AUTOSAR XML (schema 4-2-2)
package /STELLANTIS/EPT/ASWCs
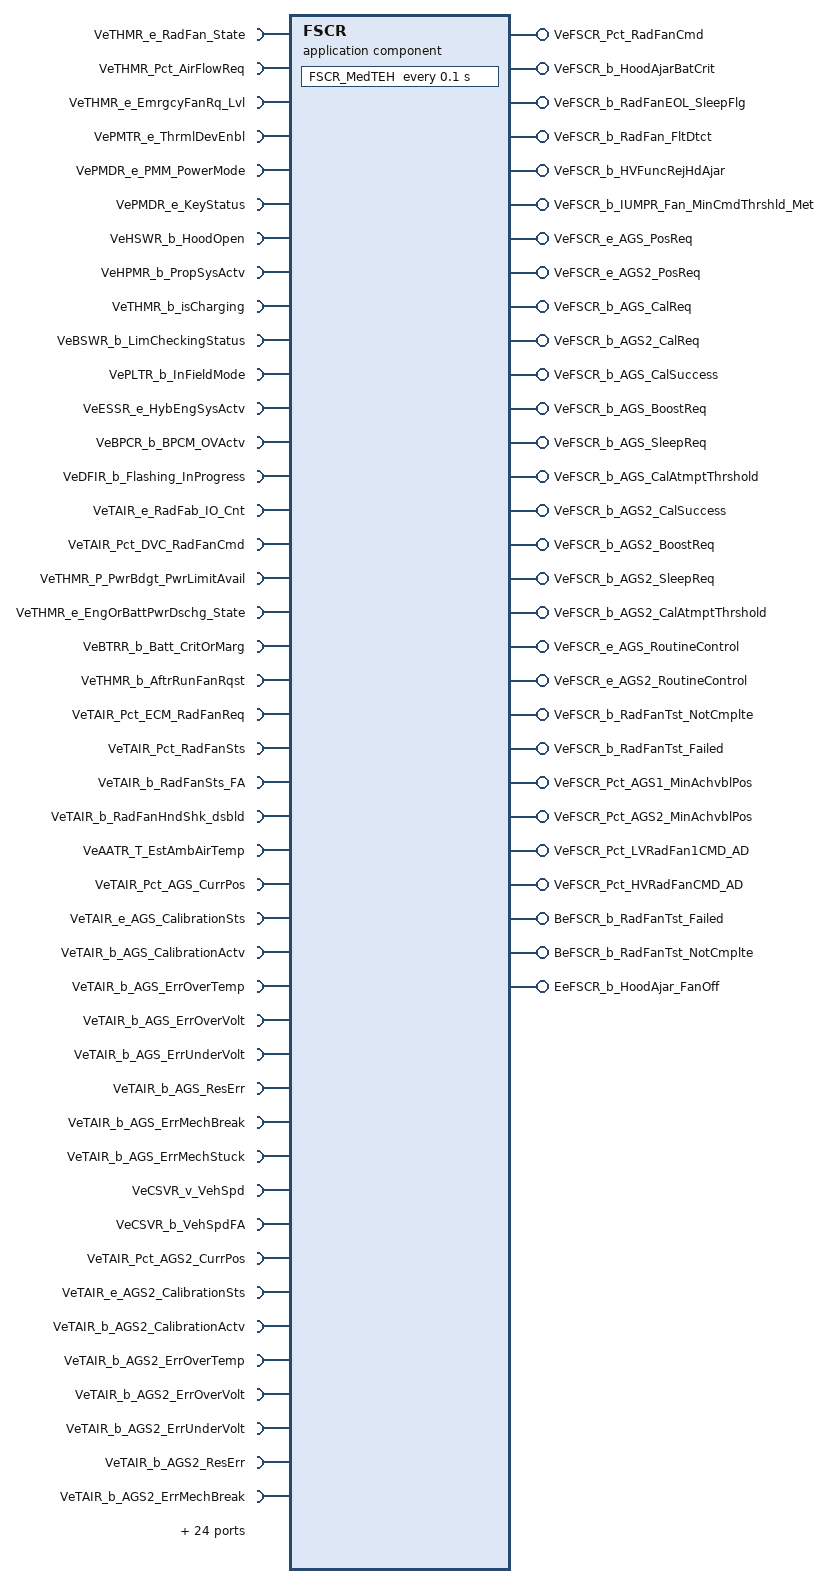
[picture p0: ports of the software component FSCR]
  application sw component type FSCR
    67 x require port:
      VeTHMR_e_RadFan_State: variation-point={short-label=vpVeTHMR_e_RadFan_State, sw-syscond=1}, nonqueued-receiver-com-spec{data-element=Value, init-value=CeFSCR_e_RadFan_OFF}, required-interface=VeTHMR_e_RadFan_State
      VeTHMR_Pct_AirFlowReq: variation-point={short-label=vpVeTHMR_Pct_AirFlowReq, sw-syscond=1}, nonqueued-receiver-com-spec{data-element=Value, init-value=0}, required-interface=VeTHMR_Pct_AirFlowReq
      VeTHMR_e_EmrgcyFanRq_Lvl: variation-point={short-label=vpVeTHMR_e_EmrgcyFanRq_Lvl, sw-syscond=1}, nonqueued-receiver-com-spec{data-element=Value, init-value=CeTHMR_e_No_EmrgcyFanRq}, required-interface=VeTHMR_e_EmrgcyFanRq_Lvl
      VePMTR_e_ThrmlDevEnbl: variation-point={short-label=vpVePMTR_e_ThrmlDevEnbl, sw-syscond=1}, nonqueued-receiver-com-spec{data-element=Value, init-value=CePMTR_e_DISBL_All_Thrml}, required-interface=VePMTR_e_ThrmlDevEnbl
      VePMDR_e_PMM_PowerMode: variation-point={short-label=vpVePMDR_e_PMM_PowerMode, sw-syscond=1}, nonqueued-receiver-com-spec{data-element=Value, init-value=CePMDR_e_PowerMode_Off}, required-interface=VePMDR_e_PMM_PowerMode
      VePMDR_e_KeyStatus: variation-point={short-label=vpVePMDR_e_KeyStatus, sw-syscond=1}, nonqueued-receiver-com-spec{data-element=Value, init-value=CePMDR_e_KeySt_Off}, required-interface=VePMDR_e_KeyStatus
      VeHSWR_b_HoodOpen: variation-point={short-label=vpVeHSWR_b_HoodOpen, sw-syscond=1}, nonqueued-receiver-com-spec{data-element=Value, init-value=0}, required-interface=VeHSWR_b_HoodOpen
      VeHPMR_b_PropSysActv: variation-point={short-label=vpVeHPMR_b_PropSysActv, sw-syscond=1}, nonqueued-receiver-com-spec{data-element=Value, init-value=0}, required-interface=VeHPMR_b_PropSysActv
      VeTHMR_b_isCharging: variation-point={short-label=vpVeTHMR_b_isCharging, sw-syscond=1}, nonqueued-receiver-com-spec{data-element=Value, init-value=0}, required-interface=VeTHMR_b_isCharging
      VeBSWR_b_LimCheckingStatus: variation-point={short-label=vpVeBSWR_b_LimCheckingStatus, sw-syscond=1}, nonqueued-receiver-com-spec{data-element=Value, init-value=0}, required-interface=VeBSWR_b_LimCheckingStatus
      VePLTR_b_InFieldMode: variation-point={short-label=vpVePLTR_b_InFieldMode, sw-syscond=1}, nonqueued-receiver-com-spec{data-element=Value, init-value=0}, required-interface=VePLTR_b_InFieldMode
      VeESSR_e_HybEngSysActv: variation-point={short-label=vpVeESSR_e_HybEngSysActv, sw-syscond=1}, nonqueued-receiver-com-spec{data-element=Value, init-value=CeESSR_e_HybEngDisabled}, required-interface=VeESSR_e_HybEngSysActv
      VeBPCR_b_BPCM_OVActv: variation-point={short-label=vpVeBPCR_b_BPCM_OVActv, sw-syscond=1}, nonqueued-receiver-com-spec{data-element=Value, init-value=0}, required-interface=VeBPCR_b_BPCM_OVActv
      VeDFIR_b_Flashing_InProgress: variation-point={short-label=vpVeDFIR_b_Flashing_InProgress, sw-syscond=1}, nonqueued-receiver-com-spec{data-element=Value, init-value=0}, required-interface=VeDFIR_b_Flashing_InProgress
      VeTAIR_e_RadFab_IO_Cnt: variation-point={short-label=vpVeTAIR_e_RadFab_IO_Cnt, sw-syscond=1}, nonqueued-receiver-com-spec{data-element=Value, init-value=CeTAIR_e_Return_Control_to_ECU}, required-interface=VeTAIR_e_RadFab_IO_Cnt
      VeTAIR_Pct_DVC_RadFanCmd: variation-point={short-label=vpVeTAIR_Pct_DVC_RadFanCmd, sw-syscond=1}, nonqueued-receiver-com-spec{data-element=Value, init-value=0}, required-interface=VeTAIR_Pct_DVC_RadFanCmd
      VeTHMR_P_PwrBdgt_PwrLimitAvail: variation-point={short-label=vpVeTHMR_P_PwrBdgt_PwrLimitAvail, sw-syscond=1}, nonqueued-receiver-com-spec{data-element=Value, init-value=0}, required-interface=VeTHMR_P_PwrBdgt_PwrLimitAvail
      VeTHMR_e_EngOrBattPwrDschg_State: variation-point={short-label=vpVeTHMR_e_EngOrBattPwrDschg_State, sw-syscond=1}, nonqueued-receiver-com-spec{data-element=Value, init-value=CePDTR_e_No_Dischrg}, required-interface=VeTHMR_e_EngOrBattPwrDschg_State
      VeBTRR_b_Batt_CritOrMarg: variation-point={short-label=vpVeBTRR_b_Batt_CritOrMarg, sw-syscond=1}, nonqueued-receiver-com-spec{data-element=Value, init-value=0}, required-interface=VeBTRR_b_Batt_CritOrMarg
      VeTHMR_b_AftrRunFanRqst: variation-point={short-label=vpVeTHMR_b_AftrRunFanRqst, sw-syscond=1}, nonqueued-receiver-com-spec{data-element=Value, init-value=0}, required-interface=VeTHMR_b_AftrRunFanRqst
      VeTAIR_Pct_ECM_RadFanReq: variation-point={short-label=vpVeTAIR_Pct_ECM_RadFanReq, sw-syscond=1}, nonqueued-receiver-com-spec{data-element=Value, init-value=0}, required-interface=VeTAIR_Pct_ECM_RadFanReq
      VeTAIR_Pct_RadFanSts: variation-point={short-label=vpVeTAIR_Pct_RadFanSts, sw-syscond=1}, nonqueued-receiver-com-spec{data-element=Value, init-value=0}, required-interface=VeTAIR_Pct_RadFanSts
      VeTAIR_b_RadFanSts_FA: variation-point={short-label=vpVeTAIR_b_RadFanSts_FA, sw-syscond=1}, nonqueued-receiver-com-spec{data-element=Value, init-value=0}, required-interface=VeTAIR_b_RadFanSts_FA
      VeTAIR_b_RadFanHndShk_dsbld: variation-point={short-label=vpVeTAIR_b_RadFanHndShk_dsbld, sw-syscond=1}, nonqueued-receiver-com-spec{data-element=Value, init-value=0}, required-interface=VeTAIR_b_RadFanHndShk_dsbld
      VeAATR_T_EstAmbAirTemp: variation-point={short-label=vpVeAATR_T_EstAmbAirTemp, sw-syscond=1}, nonqueued-receiver-com-spec{data-element=Value, init-value=0}, required-interface=VeAATR_T_EstAmbAirTemp
      VeTAIR_Pct_AGS_CurrPos: variation-point={short-label=vpVeTAIR_Pct_AGS_CurrPos, sw-syscond=1}, nonqueued-receiver-com-spec{data-element=Value, init-value=0}, required-interface=VeTAIR_Pct_AGS_CurrPos
      VeTAIR_e_AGS_CalibrationSts: variation-point={short-label=vpVeTAIR_e_AGS_CalibrationSts, sw-syscond=1}, nonqueued-receiver-com-spec{data-element=Value, init-value=CeTAIR_e_AGS_NotCalibrated}, required-interface=VeTAIR_e_AGS_CalibrationSts
      VeTAIR_b_AGS_CalibrationActv: variation-point={short-label=vpVeTAIR_b_AGS_CalibrationActv, sw-syscond=1}, nonqueued-receiver-com-spec{data-element=Value, init-value=0}, required-interface=VeTAIR_b_AGS_CalibrationActv
      VeTAIR_b_AGS_ErrOverTemp: variation-point={short-label=vpVeTAIR_b_AGS_ErrOverTemp, sw-syscond=1}, nonqueued-receiver-com-spec{data-element=Value, init-value=0}, required-interface=VeTAIR_b_AGS_ErrOverTemp
      VeTAIR_b_AGS_ErrOverVolt: variation-point={short-label=vpVeTAIR_b_AGS_ErrOverVolt, sw-syscond=1}, nonqueued-receiver-com-spec{data-element=Value, init-value=0}, required-interface=VeTAIR_b_AGS_ErrOverVolt
      VeTAIR_b_AGS_ErrUnderVolt: variation-point={short-label=vpVeTAIR_b_AGS_ErrUnderVolt, sw-syscond=1}, nonqueued-receiver-com-spec{data-element=Value, init-value=0}, required-interface=VeTAIR_b_AGS_ErrUnderVolt
      VeTAIR_b_AGS_ResErr: variation-point={short-label=vpVeTAIR_b_AGS_ResErr, sw-syscond=1}, nonqueued-receiver-com-spec{data-element=Value, init-value=0}, required-interface=VeTAIR_b_AGS_ResErr
      VeTAIR_b_AGS_ErrMechBreak: variation-point={short-label=vpVeTAIR_b_AGS_ErrMechBreak, sw-syscond=1}, nonqueued-receiver-com-spec{data-element=Value, init-value=0}, required-interface=VeTAIR_b_AGS_ErrMechBreak
      VeTAIR_b_AGS_ErrMechStuck: variation-point={short-label=vpVeTAIR_b_AGS_ErrMechStuck, sw-syscond=1}, nonqueued-receiver-com-spec{data-element=Value, init-value=0}, required-interface=VeTAIR_b_AGS_ErrMechStuck
      VeCSVR_v_VehSpd: variation-point={short-label=vpVeCSVR_v_VehSpd, sw-syscond=1}, nonqueued-receiver-com-spec{data-element=Value, init-value=0}, required-interface=VeCSVR_v_VehSpd
      VeCSVR_b_VehSpdFA: variation-point={short-label=vpVeCSVR_b_VehSpdFA, sw-syscond=1}, nonqueued-receiver-com-spec{data-element=Value, init-value=0}, required-interface=VeCSVR_b_VehSpdFA
      VeTAIR_Pct_AGS2_CurrPos: variation-point={short-label=vpVeTAIR_Pct_AGS2_CurrPos, sw-syscond=1}, nonqueued-receiver-com-spec{data-element=Value, init-value=0}, required-interface=VeTAIR_Pct_AGS2_CurrPos
      VeTAIR_e_AGS2_CalibrationSts: variation-point={short-label=vpVeTAIR_e_AGS2_CalibrationSts, sw-syscond=1}, nonqueued-receiver-com-spec{data-element=Value, init-value=CeTAIR_e_AGS_NotCalibrated}, required-interface=VeTAIR_e_AGS2_CalibrationSts
      VeTAIR_b_AGS2_CalibrationActv: variation-point={short-label=vpVeTAIR_b_AGS2_CalibrationActv, sw-syscond=1}, nonqueued-receiver-com-spec{data-element=Value, init-value=0}, required-interface=VeTAIR_b_AGS2_CalibrationActv
      VeTAIR_b_AGS2_ErrOverTemp: variation-point={short-label=vpVeTAIR_b_AGS2_ErrOverTemp, sw-syscond=1}, nonqueued-receiver-com-spec{data-element=Value, init-value=0}, required-interface=VeTAIR_b_AGS2_ErrOverTemp
      VeTAIR_b_AGS2_ErrOverVolt: variation-point={short-label=vpVeTAIR_b_AGS2_ErrOverVolt, sw-syscond=1}, nonqueued-receiver-com-spec{data-element=Value, init-value=0}, required-interface=VeTAIR_b_AGS2_ErrOverVolt
      VeTAIR_b_AGS2_ErrUnderVolt: variation-point={short-label=vpVeTAIR_b_AGS2_ErrUnderVolt, sw-syscond=1}, nonqueued-receiver-com-spec{data-element=Value, init-value=0}, required-interface=VeTAIR_b_AGS2_ErrUnderVolt
      VeTAIR_b_AGS2_ResErr: variation-point={short-label=vpVeTAIR_b_AGS2_ResErr, sw-syscond=1}, nonqueued-receiver-com-spec{data-element=Value, init-value=0}, required-interface=VeTAIR_b_AGS2_ResErr
      VeTAIR_b_AGS2_ErrMechBreak: variation-point={short-label=vpVeTAIR_b_AGS2_ErrMechBreak, sw-syscond=1}, nonqueued-receiver-com-spec{data-element=Value, init-value=0}, required-interface=VeTAIR_b_AGS2_ErrMechBreak
      VeTAIR_b_AGS2_ErrMechStuck: variation-point={short-label=vpVeTAIR_b_AGS2_ErrMechStuck, sw-syscond=1}, nonqueued-receiver-com-spec{data-element=Value, init-value=0}, required-interface=VeTAIR_b_AGS2_ErrMechStuck
      VeTAIR_b_DVC_AGS_Calibration_Start: variation-point={short-label=vpVeTAIR_b_DVC_AGS_Calibration_Start, sw-syscond=1}, nonqueued-receiver-com-spec{data-element=Value, init-value=0}, required-interface=VeTAIR_b_DVC_AGS_Calibration_Start
      VeTAIR_e_AGS_PstnCmnd: variation-point={short-label=vpVeTAIR_e_AGS_PstnCmnd, sw-syscond=1}, nonqueued-receiver-com-spec{data-element=Value, init-value=CeFSCR_e_Open100}, required-interface=VeTAIR_e_AGS_PstnCmnd
      VeTAIR_e_AGS_IO_CntrlSt: variation-point={short-label=vpVeTAIR_e_AGS_IO_CntrlSt, sw-syscond=1}, nonqueued-receiver-com-spec{data-element=Value, init-value=CeTAIR_e_Return_Control_to_ECU}, required-interface=VeTAIR_e_AGS_IO_CntrlSt
      VeTAIR_b_DVC_AGS2_Calibration_Start: variation-point={short-label=vpVeTAIR_b_DVC_AGS2_Calibration_Start, sw-syscond=1}, nonqueued-receiver-com-spec{data-element=Value, init-value=0}, required-interface=VeTAIR_b_DVC_AGS2_Calibration_Start
      VeTRNR_e_ActualGear: variation-point={short-label=vpVeTRNR_e_ActualGear, sw-syscond=1}, nonqueued-receiver-com-spec{data-element=Value, init-value=CeTRNR_e_Neutral}, required-interface=VeTRNR_e_ActualGear
      VeAPSR_Pct_AccelPedalActPosition: variation-point={short-label=vpVeAPSR_Pct_AccelPedalActPosition, sw-syscond=1}, nonqueued-receiver-com-spec{data-element=Value, init-value=0}, required-interface=VeAPSR_Pct_AccelPedalActPosition
      VeENGR_T_EngCoolantTemp: variation-point={short-label=vpVeENGR_T_EngCoolantTemp, sw-syscond=1}, nonqueued-receiver-com-spec{data-element=Value, init-value=0}, required-interface=VeENGR_T_EngCoolantTemp
      VeTMIR_T_PsvPmpClnt_TmpIn: variation-point={short-label=vpVeTMIR_T_PsvPmpClnt_TmpIn, sw-syscond=1}, nonqueued-receiver-com-spec{data-element=Value, init-value=0}, required-interface=VeTMIR_T_PsvPmpClnt_TmpIn
      VeDMAB_y_StatusByte_Fan1CntrlCktHi: variation-point={short-label=vpVeDMAB_y_StatusByte_Fan1CntrlCktHi, sw-syscond=1}, nonqueued-receiver-com-spec{data-element=Value, init-value=0}, required-interface=VeDMAB_y_StatusByte_Fan1CntrlCktHi
      VeDMAB_y_StatusByte_Fan1CntrlCktLo: variation-point={short-label=vpVeDMAB_y_StatusByte_Fan1CntrlCktLo, sw-syscond=1}, nonqueued-receiver-com-spec{data-element=Value, init-value=0}, required-interface=VeDMAB_y_StatusByte_Fan1CntrlCktLo
      VeDMAB_y_StatusByte_Fan1CntrlCkt: variation-point={short-label=vpVeDMAB_y_StatusByte_Fan1CntrlCkt, sw-syscond=1}, nonqueued-receiver-com-spec{data-element=Value, init-value=0}, required-interface=VeDMAB_y_StatusByte_Fan1CntrlCkt
      VeDMAB_y_StatusByte_RadFanDiagErrM{0..2}: variation-point={short-label=vpVeDMAB_y_StatusByte_RadFanDiagErrM{0..2}, sw-syscond=1}, nonqueued-receiver-com-spec{data-element=Value, init-value=0}, required-interface=VeDMAB_y_StatusByte_RadFanDiagErrM{0..2}
      VeTHMR_Pct_AGS_PosReq: variation-point={short-label=vpVeTHMR_Pct_AGS_PosReq, sw-syscond=1}, nonqueued-receiver-com-spec{data-element=Value, init-value=0}, required-interface=VeTHMR_Pct_AGS_PosReq
      VeTHMR_Pct_AGS2_PosReq: variation-point={short-label=vpVeTHMR_Pct_AGS2_PosReq, sw-syscond=1}, nonqueued-receiver-com-spec{data-element=Value, init-value=0}, required-interface=VeTHMR_Pct_AGS2_PosReq
      VeDCAB_b_RadFanTst_Failed_DidWrite: nonqueued-receiver-com-spec{data-element=Value, init-value=0}, required-interface=VeDCAB_b_RadFanTst_Failed_DidWrite
      VeDCAB_b_RadFanTst_NotCmplte_DidWrite: nonqueued-receiver-com-spec{data-element=Value, init-value=0}, required-interface=VeDCAB_b_RadFanTst_NotCmplte_DidWrite
      VeTHMR_Pct_FCHTRRadFanReq: variation-point={short-label=vpVeTHMR_Pct_FCHTRRadFanReq, sw-syscond=1}, nonqueued-receiver-com-spec{data-element=Value, init-value=0}, required-interface=VeTHMR_Pct_FCHTRRadFanReq
      VeTHMR_Pct_LTR_AirFlowReq: variation-point={short-label=vpVeTHMR_Pct_LTR_AirFlowReq, sw-syscond=1}, nonqueued-receiver-com-spec{data-element=Value, init-value=0}, required-interface=VeTHMR_Pct_LTR_AirFlowReq
      VeTHMR_Pct_HTR_AirFlowReq: variation-point={short-label=vpVeTHMR_Pct_HTR_AirFlowReq, sw-syscond=1}, nonqueued-receiver-com-spec{data-element=Value, init-value=0}, required-interface=VeTHMR_Pct_HTR_AirFlowReq
      VeBPCR_e_HV_BatCntctrStat: variation-point={short-label=vpVeBPCR_e_HV_BatCntctrStat, sw-syscond=1}, nonqueued-receiver-com-spec{data-element=Value, init-value=CeHVTR_e_Open}, required-interface=VeBPCR_e_HV_BatCntctrStat
    26 x provide port:
      VeFSCR_Pct_RadFanCmd: nonqueued-sender-com-spec{data-element=Value, init-value=0}, provided-interface=VeFSCR_Pct_RadFanCmd
      VeFSCR_b_HoodAjarBatCrit: nonqueued-sender-com-spec{data-element=Value, init-value=0}, provided-interface=VeFSCR_b_HoodAjarBatCrit
      VeFSCR_b_RadFanEOL_SleepFlg: nonqueued-sender-com-spec{data-element=Value, init-value=0}, provided-interface=VeFSCR_b_RadFanEOL_SleepFlg
      VeFSCR_b_RadFan_FltDtct: nonqueued-sender-com-spec{data-element=Value, init-value=0}, provided-interface=VeFSCR_b_RadFan_FltDtct
      VeFSCR_b_HVFuncRejHdAjar: nonqueued-sender-com-spec{data-element=Value, init-value=0}, provided-interface=VeFSCR_b_HVFuncRejHdAjar
      VeFSCR_b_IUMPR_Fan_MinCmdThrshld_Met: nonqueued-sender-com-spec{data-element=Value, init-value=0}, provided-interface=VeFSCR_b_IUMPR_Fan_MinCmdThrshld_Met
      VeFSCR_e_AGS_PosReq: nonqueued-sender-com-spec{data-element=Value, init-value=CeFSCR_e_Open100}, provided-interface=VeFSCR_e_AGS_PosReq
      VeFSCR_e_AGS2_PosReq: nonqueued-sender-com-spec{data-element=Value, init-value=CeFSCR_e_Open100}, provided-interface=VeFSCR_e_AGS2_PosReq
      VeFSCR_b_AGS_CalReq: nonqueued-sender-com-spec{data-element=Value, init-value=0}, provided-interface=VeFSCR_b_AGS_CalReq
      VeFSCR_b_AGS2_CalReq: nonqueued-sender-com-spec{data-element=Value, init-value=0}, provided-interface=VeFSCR_b_AGS2_CalReq
      VeFSCR_b_AGS_CalSuccess: nonqueued-sender-com-spec{data-element=Value, init-value=0}, provided-interface=VeFSCR_b_AGS_CalSuccess
      VeFSCR_b_AGS_BoostReq: nonqueued-sender-com-spec{data-element=Value, init-value=0}, provided-interface=VeFSCR_b_AGS_BoostReq
      VeFSCR_b_AGS_SleepReq: nonqueued-sender-com-spec{data-element=Value, init-value=0}, provided-interface=VeFSCR_b_AGS_SleepReq
      VeFSCR_b_AGS_CalAtmptThrshold: nonqueued-sender-com-spec{data-element=Value, init-value=0}, provided-interface=VeFSCR_b_AGS_CalAtmptThrshold
      VeFSCR_b_AGS2_CalSuccess: nonqueued-sender-com-spec{data-element=Value, init-value=0}, provided-interface=VeFSCR_b_AGS2_CalSuccess
      VeFSCR_b_AGS2_BoostReq: nonqueued-sender-com-spec{data-element=Value, init-value=0}, provided-interface=VeFSCR_b_AGS2_BoostReq
      VeFSCR_b_AGS2_SleepReq: nonqueued-sender-com-spec{data-element=Value, init-value=0}, provided-interface=VeFSCR_b_AGS2_SleepReq
      VeFSCR_b_AGS2_CalAtmptThrshold: nonqueued-sender-com-spec{data-element=Value, init-value=0}, provided-interface=VeFSCR_b_AGS2_CalAtmptThrshold
      VeFSCR_e_AGS_RoutineControl: nonqueued-sender-com-spec{data-element=Value, init-value=CeFSCR_e_AGS_Cal_In_Progress}, provided-interface=VeFSCR_e_AGS_RoutineControl
      VeFSCR_e_AGS2_RoutineControl: nonqueued-sender-com-spec{data-element=Value, init-value=CeFSCR_e_AGS_Cal_In_Progress}, provided-interface=VeFSCR_e_AGS2_RoutineControl
      VeFSCR_b_RadFanTst_NotCmplte: variation-point={short-label=vpVeFSCR_b_RadFanTst_NotCmplte, sw-syscond=1}, nonqueued-sender-com-spec{data-element=Value, init-value=0}, provided-interface=VeFSCR_b_RadFanTst_NotCmplte
      VeFSCR_b_RadFanTst_Failed: variation-point={short-label=vpVeFSCR_b_RadFanTst_Failed, sw-syscond=1}, nonqueued-sender-com-spec{data-element=Value, init-value=0}, provided-interface=VeFSCR_b_RadFanTst_Failed
      VeFSCR_Pct_AGS1_MinAchvblPos: nonqueued-sender-com-spec{data-element=Value, init-value=0}, provided-interface=VeFSCR_Pct_AGS1_MinAchvblPos
      VeFSCR_Pct_AGS2_MinAchvblPos: nonqueued-sender-com-spec{data-element=Value, init-value=0}, provided-interface=VeFSCR_Pct_AGS2_MinAchvblPos
      VeFSCR_Pct_LVRadFan1CMD_AD: nonqueued-sender-com-spec{data-element=Value, init-value=0}, provided-interface=VeFSCR_Pct_LVRadFan1CMD_AD
      VeFSCR_Pct_HVRadFanCMD_AD: nonqueued-sender-com-spec{data-element=Value, init-value=0}, provided-interface=VeFSCR_Pct_HVRadFanCMD_AD
    require port BeFSCR_b_RadFanTst_Failed_Rx: variation-point={short-label=vpBeFSCR_b_RadFanTst_Failed_Rx, sw-syscond=1}, nv-require-com-spec{init-value=0, variable=BeFSCR_b_RadFanTst_Failed}, required-interface=BeFSCR_b_RadFanTst_Failed
    require port BeFSCR_b_RadFanTst_NotCmplte_Rx: variation-point={short-label=vpBeFSCR_b_RadFanTst_NotCmplte_Rx, sw-syscond=1}, nv-require-com-spec{init-value=0, variable=BeFSCR_b_RadFanTst_NotCmplte}, required-interface=BeFSCR_b_RadFanTst_NotCmplte
    require port EeFSCR_b_HoodAjar_FanOff_Rx: variation-point={short-label=vpEeFSCR_b_HoodAjar_FanOff_Rx, sw-syscond=1}, nv-require-com-spec{init-value=0, variable=EeFSCR_b_HoodAjar_FanOff}, required-interface=EeFSCR_b_HoodAjar_FanOff
    provide port BeFSCR_b_RadFanTst_Failed: variation-point={short-label=vpBeFSCR_b_RadFanTst_Failed, sw-syscond=1}, nv-provide-com-spec{ram-block-init-value=0, variable=BeFSCR_b_RadFanTst_Failed}, provided-interface=BeFSCR_b_RadFanTst_Failed
    provide port BeFSCR_b_RadFanTst_NotCmplte: variation-point={short-label=vpBeFSCR_b_RadFanTst_NotCmplte, sw-syscond=1}, nv-provide-com-spec{ram-block-init-value=0, variable=BeFSCR_b_RadFanTst_NotCmplte}, provided-interface=BeFSCR_b_RadFanTst_NotCmplte
    provide port EeFSCR_b_HoodAjar_FanOff: variation-point={short-label=vpEeFSCR_b_HoodAjar_FanOff, sw-syscond=1}, nv-provide-com-spec{ram-block-init-value=0, variable=EeFSCR_b_HoodAjar_FanOff}, provided-interface=EeFSCR_b_HoodAjar_FanOff
    behavior IB_FSCR: data-type-mapping=msADTtoIDTMapping, handle-termination-and-restart=NO-SUPPORT
      timing event Event_MedTEH: start-on-event=FSCR_MedTEH, period=0.1
      init event Event_FSCR_ac_Init: start-on-event=FSCR_ac_Init
      init event Event_PwrOn: start-on-event=FSCR_PwrOn
      init event Event_PwrOff: start-on-event=FSCR_PwrOff
      data received event Event_DIDWrite_RadFanTst: start-on-event=DIDWrite_RadFanTst, data=VeDCAB_b_RadFanTst_Failed_DidWrite.Value
      5 x runnable:
        FSCR_ac_Init
          data-send-points:
            4 x access:
              OUT_VeFSCR_e_AGS_PosReq_Value: accessed-variable=VeFSCR_e_AGS_PosReq.Value
              OUT_VeFSCR_e_AGS2_PosReq_Value: accessed-variable=VeFSCR_e_AGS2_PosReq.Value
              OUT_VeFSCR_e_AGS_RoutineControl_Value: accessed-variable=VeFSCR_e_AGS_RoutineControl.Value
              OUT_VeFSCR_e_AGS2_RoutineControl_Value: accessed-variable=VeFSCR_e_AGS2_RoutineControl.Value
        FSCR_PwrOn
          data-receive-point-by-arguments:
            access IN_BeFSCR_b_RadFanTst_Failed_Rx_BeFSCR_b_RadFanTst_Failed: accessed-variable=BeFSCR_b_RadFanTst_Failed_Rx.BeFSCR_b_RadFanTst_Failed, variation-point={short-label=vpIN_BeFSCR_b_RadFanTst_Failed_Rx_BeFSCR_b_RadFanTst_Failed, sw-syscond=1}
            access IN_BeFSCR_b_RadFanTst_NotCmplte_Rx_BeFSCR_b_RadFanTst_NotCmplte: accessed-variable=BeFSCR_b_RadFanTst_NotCmplte_Rx.BeFSCR_b_RadFanTst_NotCmplte, variation-point={short-label=vpIN_BeFSCR_b_RadFanTst_NotCmplte_Rx_BeFSCR_b_RadFanTst_NotCmplte, sw-syscond=1}
            access IN_EeFSCR_b_HoodAjar_FanOff_Rx_EeFSCR_b_HoodAjar_FanOff: accessed-variable=EeFSCR_b_HoodAjar_FanOff_Rx.EeFSCR_b_HoodAjar_FanOff, variation-point={short-label=vpIN_EeFSCR_b_HoodAjar_FanOff_Rx_EeFSCR_b_HoodAjar_FanOff, sw-syscond=1}
          data-send-points:
            26 x access:
              OUT_VeFSCR_Pct_RadFanCmd_Value: accessed-variable=VeFSCR_Pct_RadFanCmd.Value
              OUT_VeFSCR_b_AGS2_CalReq_Value: accessed-variable=VeFSCR_b_AGS2_CalReq.Value
              OUT_VeFSCR_b_AGS_CalSuccess_Value: accessed-variable=VeFSCR_b_AGS_CalSuccess.Value
              OUT_VeFSCR_b_AGS_BoostReq_Value: accessed-variable=VeFSCR_b_AGS_BoostReq.Value
              OUT_VeFSCR_b_AGS_SleepReq_Value: accessed-variable=VeFSCR_b_AGS_SleepReq.Value
              OUT_VeFSCR_b_AGS_CalAtmptThrshold_Value: accessed-variable=VeFSCR_b_AGS_CalAtmptThrshold.Value
              OUT_VeFSCR_b_AGS2_CalSuccess_Value: accessed-variable=VeFSCR_b_AGS2_CalSuccess.Value
              OUT_VeFSCR_b_AGS2_BoostReq_Value: accessed-variable=VeFSCR_b_AGS2_BoostReq.Value
              OUT_VeFSCR_b_AGS2_SleepReq_Value: accessed-variable=VeFSCR_b_AGS2_SleepReq.Value
              OUT_VeFSCR_b_AGS2_CalAtmptThrshold_Value: accessed-variable=VeFSCR_b_AGS2_CalAtmptThrshold.Value
              OUT_VeFSCR_e_AGS_RoutineControl_Value: accessed-variable=VeFSCR_e_AGS_RoutineControl.Value
              OUT_VeFSCR_b_HoodAjarBatCrit_Value: accessed-variable=VeFSCR_b_HoodAjarBatCrit.Value
              OUT_VeFSCR_e_AGS2_RoutineControl_Value: accessed-variable=VeFSCR_e_AGS2_RoutineControl.Value
              OUT_VeFSCR_b_RadFan_FltDtct_Value: accessed-variable=VeFSCR_b_RadFan_FltDtct.Value
              OUT_VeFSCR_b_HVFuncRejHdAjar_Value: accessed-variable=VeFSCR_b_HVFuncRejHdAjar.Value
              OUT_VeFSCR_b_RadFanEOL_SleepFlg_Value: accessed-variable=VeFSCR_b_RadFanEOL_SleepFlg.Value
              OUT_VeFSCR_b_IUMPR_Fan_MinCmdThrshld_Met_Value: accessed-variable=VeFSCR_b_IUMPR_Fan_MinCmdThrshld_Met.Value
              OUT_VeFSCR_e_AGS_PosReq_Value: accessed-variable=VeFSCR_e_AGS_PosReq.Value
              OUT_VeFSCR_e_AGS2_PosReq_Value: accessed-variable=VeFSCR_e_AGS2_PosReq.Value
              OUT_VeFSCR_b_AGS_CalReq_Value: accessed-variable=VeFSCR_b_AGS_CalReq.Value
              OUT_VeFSCR_b_RadFanTst_NotCmplte_Value: accessed-variable=VeFSCR_b_RadFanTst_NotCmplte.Value, variation-point={short-label=vpOUT_VeFSCR_b_RadFanTst_NotCmplte_Value, sw-syscond=1}
              OUT_VeFSCR_b_RadFanTst_Failed_Value: accessed-variable=VeFSCR_b_RadFanTst_Failed.Value, variation-point={short-label=vpOUT_VeFSCR_b_RadFanTst_Failed_Value, sw-syscond=1}
              OUT_VeFSCR_Pct_AGS1_MinAchvblPos_Value: accessed-variable=VeFSCR_Pct_AGS1_MinAchvblPos.Value
              OUT_VeFSCR_Pct_AGS2_MinAchvblPos_Value: accessed-variable=VeFSCR_Pct_AGS2_MinAchvblPos.Value
              OUT_VeFSCR_Pct_LVRadFan1CMD_AD_Value: accessed-variable=VeFSCR_Pct_LVRadFan1CMD_AD.Value
              OUT_VeFSCR_Pct_HVRadFanCMD_AD_Value: accessed-variable=VeFSCR_Pct_HVRadFanCMD_AD.Value
        FSCR_MedTEH: variation-point={short-label=vpFSCR_MedTEH, sw-syscond=1}
          data-receive-point-by-arguments:
            65 x access:
              IN_VeAATR_T_EstAmbAirTemp_Value: accessed-variable=VeAATR_T_EstAmbAirTemp.Value, variation-point={short-label=vpIN_VeAATR_T_EstAmbAirTemp_Value, sw-syscond=1}
              IN_VeAPSR_Pct_AccelPedalActPosition_Value: accessed-variable=VeAPSR_Pct_AccelPedalActPosition.Value, variation-point={short-label=vpIN_VeAPSR_Pct_AccelPedalActPosition_Value, sw-syscond=1}
              IN_VeBPCR_b_BPCM_OVActv_Value: accessed-variable=VeBPCR_b_BPCM_OVActv.Value, variation-point={short-label=vpIN_VeBPCR_b_BPCM_OVActv_Value, sw-syscond=1}
              IN_VeBPCR_e_HV_BatCntctrStat_Value: accessed-variable=VeBPCR_e_HV_BatCntctrStat.Value, variation-point={short-label=vpIN_VeBPCR_e_HV_BatCntctrStat_Value, sw-syscond=1}
              IN_VeBSWR_b_LimCheckingStatus_Value: accessed-variable=VeBSWR_b_LimCheckingStatus.Value, variation-point={short-label=vpIN_VeBSWR_b_LimCheckingStatus_Value, sw-syscond=1}
              IN_VeBTRR_b_Batt_CritOrMarg_Value: accessed-variable=VeBTRR_b_Batt_CritOrMarg.Value, variation-point={short-label=vpIN_VeBTRR_b_Batt_CritOrMarg_Value, sw-syscond=1}
              IN_VeCSVR_b_VehSpdFA_Value: accessed-variable=VeCSVR_b_VehSpdFA.Value, variation-point={short-label=vpIN_VeCSVR_b_VehSpdFA_Value, sw-syscond=1}
              IN_VeCSVR_v_VehSpd_Value: accessed-variable=VeCSVR_v_VehSpd.Value, variation-point={short-label=vpIN_VeCSVR_v_VehSpd_Value, sw-syscond=1}
              IN_VeDFIR_b_Flashing_InProgress_Value: accessed-variable=VeDFIR_b_Flashing_InProgress.Value, variation-point={short-label=vpIN_VeDFIR_b_Flashing_InProgress_Value, sw-syscond=1}
              IN_VeDMAB_y_StatusByte_Fan1CntrlCkt_Value: accessed-variable=VeDMAB_y_StatusByte_Fan1CntrlCkt.Value, variation-point={short-label=vpIN_VeDMAB_y_StatusByte_Fan1CntrlCkt_Value, sw-syscond=1}
              IN_VeDMAB_y_StatusByte_Fan1CntrlCktHi_Value: accessed-variable=VeDMAB_y_StatusByte_Fan1CntrlCktHi.Value, variation-point={short-label=vpIN_VeDMAB_y_StatusByte_Fan1CntrlCktHi_Value, sw-syscond=1}
              IN_VeDMAB_y_StatusByte_Fan1CntrlCktLo_Value: accessed-variable=VeDMAB_y_StatusByte_Fan1CntrlCktLo.Value, variation-point={short-label=vpIN_VeDMAB_y_StatusByte_Fan1CntrlCktLo_Value, sw-syscond=1}
              IN_VeDMAB_y_StatusByte_RadFanDiagErrM{0..2}_Value: accessed-variable=VeDMAB_y_StatusByte_RadFanDiagErrM{0..2}.Value, variation-point={short-label=vpIN_VeDMAB_y_StatusByte_RadFanDiagErrM{0..2}_Value, sw-syscond=1}
              IN_VeENGR_T_EngCoolantTemp_Value: accessed-variable=VeENGR_T_EngCoolantTemp.Value, variation-point={short-label=vpIN_VeENGR_T_EngCoolantTemp_Value, sw-syscond=1}
              IN_VeESSR_e_HybEngSysActv_Value: accessed-variable=VeESSR_e_HybEngSysActv.Value, variation-point={short-label=vpIN_VeESSR_e_HybEngSysActv_Value, sw-syscond=1}
              IN_VeHPMR_b_PropSysActv_Value: accessed-variable=VeHPMR_b_PropSysActv.Value, variation-point={short-label=vpIN_VeHPMR_b_PropSysActv_Value, sw-syscond=1}
              IN_VeHSWR_b_HoodOpen_Value: accessed-variable=VeHSWR_b_HoodOpen.Value, variation-point={short-label=vpIN_VeHSWR_b_HoodOpen_Value, sw-syscond=1}
              IN_VePLTR_b_InFieldMode_Value: accessed-variable=VePLTR_b_InFieldMode.Value, variation-point={short-label=vpIN_VePLTR_b_InFieldMode_Value, sw-syscond=1}
              IN_VePMDR_e_KeyStatus_Value: accessed-variable=VePMDR_e_KeyStatus.Value, variation-point={short-label=vpIN_VePMDR_e_KeyStatus_Value, sw-syscond=1}
              IN_VePMDR_e_PMM_PowerMode_Value: accessed-variable=VePMDR_e_PMM_PowerMode.Value, variation-point={short-label=vpIN_VePMDR_e_PMM_PowerMode_Value, sw-syscond=1}
              IN_VePMTR_e_ThrmlDevEnbl_Value: accessed-variable=VePMTR_e_ThrmlDevEnbl.Value, variation-point={short-label=vpIN_VePMTR_e_ThrmlDevEnbl_Value, sw-syscond=1}
              IN_VeTAIR_Pct_AGS2_CurrPos_Value: accessed-variable=VeTAIR_Pct_AGS2_CurrPos.Value, variation-point={short-label=vpIN_VeTAIR_Pct_AGS2_CurrPos_Value, sw-syscond=1}
              IN_VeTAIR_Pct_AGS_CurrPos_Value: accessed-variable=VeTAIR_Pct_AGS_CurrPos.Value, variation-point={short-label=vpIN_VeTAIR_Pct_AGS_CurrPos_Value, sw-syscond=1}
              IN_VeTAIR_Pct_DVC_RadFanCmd_Value: accessed-variable=VeTAIR_Pct_DVC_RadFanCmd.Value, variation-point={short-label=vpIN_VeTAIR_Pct_DVC_RadFanCmd_Value, sw-syscond=1}
              IN_VeTAIR_Pct_ECM_RadFanReq_Value: accessed-variable=VeTAIR_Pct_ECM_RadFanReq.Value, variation-point={short-label=vpIN_VeTAIR_Pct_ECM_RadFanReq_Value, sw-syscond=1}
              IN_VeTAIR_Pct_RadFanSts_Value: accessed-variable=VeTAIR_Pct_RadFanSts.Value, variation-point={short-label=vpIN_VeTAIR_Pct_RadFanSts_Value, sw-syscond=1}
              IN_VeTAIR_b_AGS2_CalibrationActv_Value: accessed-variable=VeTAIR_b_AGS2_CalibrationActv.Value, variation-point={short-label=vpIN_VeTAIR_b_AGS2_CalibrationActv_Value, sw-syscond=1}
              IN_VeTAIR_b_AGS2_ErrMechBreak_Value: accessed-variable=VeTAIR_b_AGS2_ErrMechBreak.Value, variation-point={short-label=vpIN_VeTAIR_b_AGS2_ErrMechBreak_Value, sw-syscond=1}
              IN_VeTAIR_b_AGS2_ErrMechStuck_Value: accessed-variable=VeTAIR_b_AGS2_ErrMechStuck.Value, variation-point={short-label=vpIN_VeTAIR_b_AGS2_ErrMechStuck_Value, sw-syscond=1}
              IN_VeTAIR_b_AGS2_ErrOverTemp_Value: accessed-variable=VeTAIR_b_AGS2_ErrOverTemp.Value, variation-point={short-label=vpIN_VeTAIR_b_AGS2_ErrOverTemp_Value, sw-syscond=1}
              IN_VeTAIR_b_AGS2_ErrOverVolt_Value: accessed-variable=VeTAIR_b_AGS2_ErrOverVolt.Value, variation-point={short-label=vpIN_VeTAIR_b_AGS2_ErrOverVolt_Value, sw-syscond=1}
              IN_VeTAIR_b_AGS2_ErrUnderVolt_Value: accessed-variable=VeTAIR_b_AGS2_ErrUnderVolt.Value, variation-point={short-label=vpIN_VeTAIR_b_AGS2_ErrUnderVolt_Value, sw-syscond=1}
              IN_VeTAIR_b_AGS2_ResErr_Value: accessed-variable=VeTAIR_b_AGS2_ResErr.Value, variation-point={short-label=vpIN_VeTAIR_b_AGS2_ResErr_Value, sw-syscond=1}
              IN_VeTAIR_b_AGS_CalibrationActv_Value: accessed-variable=VeTAIR_b_AGS_CalibrationActv.Value, variation-point={short-label=vpIN_VeTAIR_b_AGS_CalibrationActv_Value, sw-syscond=1}
              IN_VeTAIR_b_AGS_ErrMechBreak_Value: accessed-variable=VeTAIR_b_AGS_ErrMechBreak.Value, variation-point={short-label=vpIN_VeTAIR_b_AGS_ErrMechBreak_Value, sw-syscond=1}
              IN_VeTAIR_b_AGS_ErrMechStuck_Value: accessed-variable=VeTAIR_b_AGS_ErrMechStuck.Value, variation-point={short-label=vpIN_VeTAIR_b_AGS_ErrMechStuck_Value, sw-syscond=1}
              IN_VeTAIR_b_AGS_ErrOverTemp_Value: accessed-variable=VeTAIR_b_AGS_ErrOverTemp.Value, variation-point={short-label=vpIN_VeTAIR_b_AGS_ErrOverTemp_Value, sw-syscond=1}
              IN_VeTAIR_b_AGS_ErrOverVolt_Value: accessed-variable=VeTAIR_b_AGS_ErrOverVolt.Value, variation-point={short-label=vpIN_VeTAIR_b_AGS_ErrOverVolt_Value, sw-syscond=1}
              IN_VeTAIR_b_AGS_ErrUnderVolt_Value: accessed-variable=VeTAIR_b_AGS_ErrUnderVolt.Value, variation-point={short-label=vpIN_VeTAIR_b_AGS_ErrUnderVolt_Value, sw-syscond=1}
              IN_VeTAIR_b_AGS_ResErr_Value: accessed-variable=VeTAIR_b_AGS_ResErr.Value, variation-point={short-label=vpIN_VeTAIR_b_AGS_ResErr_Value, sw-syscond=1}
              IN_VeTAIR_b_DVC_AGS2_Calibration_Start_Value: accessed-variable=VeTAIR_b_DVC_AGS2_Calibration_Start.Value, variation-point={short-label=vpIN_VeTAIR_b_DVC_AGS2_Calibration_Start_Value, sw-syscond=1}
              IN_VeTAIR_b_DVC_AGS_Calibration_Start_Value: accessed-variable=VeTAIR_b_DVC_AGS_Calibration_Start.Value, variation-point={short-label=vpIN_VeTAIR_b_DVC_AGS_Calibration_Start_Value, sw-syscond=1}
              IN_VeTAIR_b_RadFanHndShk_dsbld_Value: accessed-variable=VeTAIR_b_RadFanHndShk_dsbld.Value, variation-point={short-label=vpIN_VeTAIR_b_RadFanHndShk_dsbld_Value, sw-syscond=1}
              IN_VeTAIR_b_RadFanSts_FA_Value: accessed-variable=VeTAIR_b_RadFanSts_FA.Value, variation-point={short-label=vpIN_VeTAIR_b_RadFanSts_FA_Value, sw-syscond=1}
              IN_VeTAIR_e_AGS2_CalibrationSts_Value: accessed-variable=VeTAIR_e_AGS2_CalibrationSts.Value, variation-point={short-label=vpIN_VeTAIR_e_AGS2_CalibrationSts_Value, sw-syscond=1}
              IN_VeTAIR_e_AGS_CalibrationSts_Value: accessed-variable=VeTAIR_e_AGS_CalibrationSts.Value, variation-point={short-label=vpIN_VeTAIR_e_AGS_CalibrationSts_Value, sw-syscond=1}
              IN_VeTAIR_e_AGS_IO_CntrlSt_Value: accessed-variable=VeTAIR_e_AGS_IO_CntrlSt.Value, variation-point={short-label=vpIN_VeTAIR_e_AGS_IO_CntrlSt_Value, sw-syscond=1}
              IN_VeTAIR_e_AGS_PstnCmnd_Value: accessed-variable=VeTAIR_e_AGS_PstnCmnd.Value, variation-point={short-label=vpIN_VeTAIR_e_AGS_PstnCmnd_Value, sw-syscond=1}
              IN_VeTAIR_e_RadFab_IO_Cnt_Value: accessed-variable=VeTAIR_e_RadFab_IO_Cnt.Value, variation-point={short-label=vpIN_VeTAIR_e_RadFab_IO_Cnt_Value, sw-syscond=1}
              IN_VeTHMR_P_PwrBdgt_PwrLimitAvail_Value: accessed-variable=VeTHMR_P_PwrBdgt_PwrLimitAvail.Value, variation-point={short-label=vpIN_VeTHMR_P_PwrBdgt_PwrLimitAvail_Value, sw-syscond=1}
              IN_VeTHMR_Pct_AGS2_PosReq_Value: accessed-variable=VeTHMR_Pct_AGS2_PosReq.Value, variation-point={short-label=vpIN_VeTHMR_Pct_AGS2_PosReq_Value, sw-syscond=1}
              IN_VeTHMR_Pct_AGS_PosReq_Value: accessed-variable=VeTHMR_Pct_AGS_PosReq.Value, variation-point={short-label=vpIN_VeTHMR_Pct_AGS_PosReq_Value, sw-syscond=1}
              IN_VeTHMR_Pct_AirFlowReq_Value: accessed-variable=VeTHMR_Pct_AirFlowReq.Value, variation-point={short-label=vpIN_VeTHMR_Pct_AirFlowReq_Value, sw-syscond=1}
              IN_VeTHMR_Pct_FCHTRRadFanReq_Value: accessed-variable=VeTHMR_Pct_FCHTRRadFanReq.Value, variation-point={short-label=vpIN_VeTHMR_Pct_FCHTRRadFanReq_Value, sw-syscond=1}
              IN_VeTHMR_Pct_HTR_AirFlowReq_Value: accessed-variable=VeTHMR_Pct_HTR_AirFlowReq.Value, variation-point={short-label=vpIN_VeTHMR_Pct_HTR_AirFlowReq_Value, sw-syscond=1}
              IN_VeTHMR_Pct_LTR_AirFlowReq_Value: accessed-variable=VeTHMR_Pct_LTR_AirFlowReq.Value, variation-point={short-label=vpIN_VeTHMR_Pct_LTR_AirFlowReq_Value, sw-syscond=1}
              IN_VeTHMR_b_AftrRunFanRqst_Value: accessed-variable=VeTHMR_b_AftrRunFanRqst.Value, variation-point={short-label=vpIN_VeTHMR_b_AftrRunFanRqst_Value, sw-syscond=1}
              IN_VeTHMR_b_isCharging_Value: accessed-variable=VeTHMR_b_isCharging.Value, variation-point={short-label=vpIN_VeTHMR_b_isCharging_Value, sw-syscond=1}
              IN_VeTHMR_e_EmrgcyFanRq_Lvl_Value: accessed-variable=VeTHMR_e_EmrgcyFanRq_Lvl.Value, variation-point={short-label=vpIN_VeTHMR_e_EmrgcyFanRq_Lvl_Value, sw-syscond=1}
              IN_VeTHMR_e_EngOrBattPwrDschg_State_Value: accessed-variable=VeTHMR_e_EngOrBattPwrDschg_State.Value, variation-point={short-label=vpIN_VeTHMR_e_EngOrBattPwrDschg_State_Value, sw-syscond=1}
              IN_VeTHMR_e_RadFan_State_Value: accessed-variable=VeTHMR_e_RadFan_State.Value, variation-point={short-label=vpIN_VeTHMR_e_RadFan_State_Value, sw-syscond=1}
              IN_VeTMIR_T_PsvPmpClnt_TmpIn_Value: accessed-variable=VeTMIR_T_PsvPmpClnt_TmpIn.Value, variation-point={short-label=vpIN_VeTMIR_T_PsvPmpClnt_TmpIn_Value, sw-syscond=1}
              IN_VeTRNR_e_ActualGear_Value: accessed-variable=VeTRNR_e_ActualGear.Value, variation-point={short-label=vpIN_VeTRNR_e_ActualGear_Value, sw-syscond=1}
          data-send-points:
            26 x access:
              OUT_VeFSCR_Pct_RadFanCmd_Value: accessed-variable=VeFSCR_Pct_RadFanCmd.Value
              OUT_VeFSCR_b_AGS2_CalReq_Value: accessed-variable=VeFSCR_b_AGS2_CalReq.Value
              OUT_VeFSCR_b_AGS_CalSuccess_Value: accessed-variable=VeFSCR_b_AGS_CalSuccess.Value
              OUT_VeFSCR_b_AGS_BoostReq_Value: accessed-variable=VeFSCR_b_AGS_BoostReq.Value
              OUT_VeFSCR_b_AGS_SleepReq_Value: accessed-variable=VeFSCR_b_AGS_SleepReq.Value
              OUT_VeFSCR_b_AGS_CalAtmptThrshold_Value: accessed-variable=VeFSCR_b_AGS_CalAtmptThrshold.Value
              OUT_VeFSCR_b_AGS2_CalSuccess_Value: accessed-variable=VeFSCR_b_AGS2_CalSuccess.Value
              OUT_VeFSCR_b_AGS2_BoostReq_Value: accessed-variable=VeFSCR_b_AGS2_BoostReq.Value
              OUT_VeFSCR_b_AGS2_SleepReq_Value: accessed-variable=VeFSCR_b_AGS2_SleepReq.Value
              OUT_VeFSCR_b_AGS2_CalAtmptThrshold_Value: accessed-variable=VeFSCR_b_AGS2_CalAtmptThrshold.Value
              OUT_VeFSCR_e_AGS_RoutineControl_Value: accessed-variable=VeFSCR_e_AGS_RoutineControl.Value
              OUT_VeFSCR_b_HoodAjarBatCrit_Value: accessed-variable=VeFSCR_b_HoodAjarBatCrit.Value
              OUT_VeFSCR_e_AGS2_RoutineControl_Value: accessed-variable=VeFSCR_e_AGS2_RoutineControl.Value
              OUT_VeFSCR_b_RadFan_FltDtct_Value: accessed-variable=VeFSCR_b_RadFan_FltDtct.Value
              OUT_VeFSCR_b_HVFuncRejHdAjar_Value: accessed-variable=VeFSCR_b_HVFuncRejHdAjar.Value
              OUT_VeFSCR_b_RadFanEOL_SleepFlg_Value: accessed-variable=VeFSCR_b_RadFanEOL_SleepFlg.Value
              OUT_VeFSCR_b_IUMPR_Fan_MinCmdThrshld_Met_Value: accessed-variable=VeFSCR_b_IUMPR_Fan_MinCmdThrshld_Met.Value
              OUT_VeFSCR_e_AGS_PosReq_Value: accessed-variable=VeFSCR_e_AGS_PosReq.Value
              OUT_VeFSCR_e_AGS2_PosReq_Value: accessed-variable=VeFSCR_e_AGS2_PosReq.Value
              OUT_VeFSCR_b_AGS_CalReq_Value: accessed-variable=VeFSCR_b_AGS_CalReq.Value
              OUT_VeFSCR_b_RadFanTst_NotCmplte_Value: accessed-variable=VeFSCR_b_RadFanTst_NotCmplte.Value, variation-point={short-label=vpOUT_VeFSCR_b_RadFanTst_NotCmplte_Value, sw-syscond=1}
              OUT_VeFSCR_b_RadFanTst_Failed_Value: accessed-variable=VeFSCR_b_RadFanTst_Failed.Value, variation-point={short-label=vpOUT_VeFSCR_b_RadFanTst_Failed_Value, sw-syscond=1}
              OUT_VeFSCR_Pct_AGS1_MinAchvblPos_Value: accessed-variable=VeFSCR_Pct_AGS1_MinAchvblPos.Value
              OUT_VeFSCR_Pct_AGS2_MinAchvblPos_Value: accessed-variable=VeFSCR_Pct_AGS2_MinAchvblPos.Value
              OUT_VeFSCR_Pct_LVRadFan1CMD_AD_Value: accessed-variable=VeFSCR_Pct_LVRadFan1CMD_AD.Value
              OUT_VeFSCR_Pct_HVRadFanCMD_AD_Value: accessed-variable=VeFSCR_Pct_HVRadFanCMD_AD.Value
        FSCR_PwrOff: variation-point={short-label=vpFSCR_PwrOff, sw-syscond=1}
          data-send-points:
            access OUT_BeFSCR_b_RadFanTst_Failed_BeFSCR_b_RadFanTst_Failed: accessed-variable=BeFSCR_b_RadFanTst_Failed.BeFSCR_b_RadFanTst_Failed, variation-point={short-label=vpOUT_BeFSCR_b_RadFanTst_Failed_BeFSCR_b_RadFanTst_Failed, sw-syscond=1}
            access OUT_BeFSCR_b_RadFanTst_NotCmplte_BeFSCR_b_RadFanTst_NotCmplte: accessed-variable=BeFSCR_b_RadFanTst_NotCmplte.BeFSCR_b_RadFanTst_NotCmplte, variation-point={short-label=vpOUT_BeFSCR_b_RadFanTst_NotCmplte_BeFSCR_b_RadFanTst_NotCmplte, sw-syscond=1}
            access OUT_EeFSCR_b_HoodAjar_FanOff_EeFSCR_b_HoodAjar_FanOff: accessed-variable=EeFSCR_b_HoodAjar_FanOff.EeFSCR_b_HoodAjar_FanOff, variation-point={short-label=vpOUT_EeFSCR_b_HoodAjar_FanOff_EeFSCR_b_HoodAjar_FanOff, sw-syscond=1}
        DIDWrite_RadFanTst
          data-receive-point-by-arguments:
            access IN_VeDCAB_b_RadFanTst_Failed_DidWrite_Value: accessed-variable=VeDCAB_b_RadFanTst_Failed_DidWrite.Value
            access IN_VeDCAB_b_RadFanTst_NotCmplte_DidWrite_Value: accessed-variable=VeDCAB_b_RadFanTst_NotCmplte_DidWrite.Value
      4 x variation point proxy, all with category=CONDITION:
        Variant_FSCR_FUNC_1: condition-access=1
        Variant_FSCR_FUNC_2: condition-access=0
        Variant_FSCR_FUNC_3: condition-access=1
        Variant_FSCR_FUNC_4: condition-access=0
